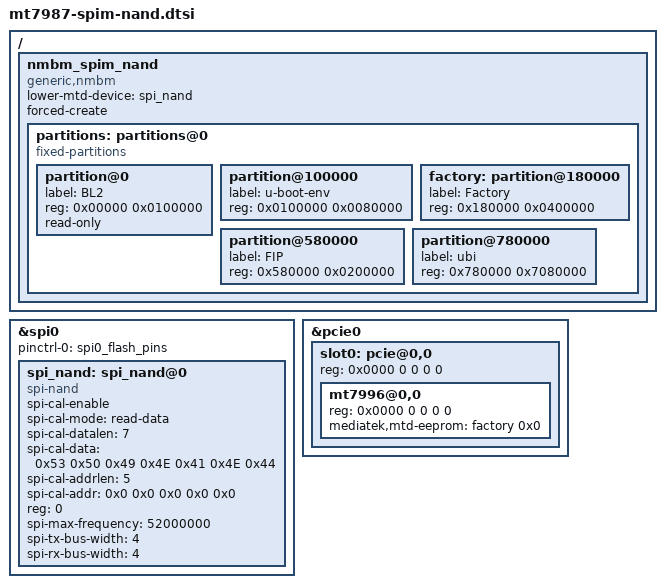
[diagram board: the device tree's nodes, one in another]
/* SPDX-License-Identifier: (GPL-2.0-only OR MIT) */

#include "mt7987-pinctrl.dtsi"

/ {
	nmbm_spim_nand {
		compatible = "generic,nmbm";

		#address-cells = <1>;
		#size-cells = <1>;

		lower-mtd-device = <&spi_nand>;
		forced-create;

		partitions: partitions@0 {
			compatible = "fixed-partitions";
			#address-cells = <1>;
			#size-cells = <1>;
		};
	};
};

&partitions {
	partition@0 {
		label = "BL2";
		reg = <0x00000 0x0100000>;
		read-only;
	};
	partition@100000 {
		label = "u-boot-env";
		reg = <0x0100000 0x0080000>;
	};
	factory: partition@180000 {
		label = "Factory";
		reg = <0x180000 0x0400000>;
	};
	partition@580000 {
		label = "FIP";
		reg = <0x580000 0x0200000>;
	};
	partition@780000 {
		label = "ubi";
		reg = <0x780000 0x7080000>;
	};
};

&spi0 {
	pinctrl-names = "default";
	pinctrl-0 = <&spi0_flash_pins>;
	status = "okay";
	#address-cells = <1>;
	#size-cells = <0>;

	spi_nand: spi_nand@0 {
		#address-cells = <1>;
		#size-cells = <1>;
		compatible = "spi-nand";
		spi-cal-enable;
		spi-cal-mode = "read-data";
		spi-cal-datalen = <7>;
		spi-cal-data = /bits/ 8 <0x53 0x50 0x49 0x4E 0x41 0x4E 0x44>;
		spi-cal-addrlen = <5>;
		spi-cal-addr = /bits/ 32 <0x0 0x0 0x0 0x0 0x0>;
		reg = <0>;
		spi-max-frequency = <52000000>;
		spi-tx-bus-width = <4>;
		spi-rx-bus-width = <4>;
	};
};

&pcie0 {
	/* slot0 is used for MT76 only */
	slot0: pcie@0,0 {
		reg = <0x0000 0 0 0 0>;

		mt7996@0,0 {
			reg = <0x0000 0 0 0 0>;
			device_type = "pci";
			mediatek,mtd-eeprom = <&factory 0x0>;
		};
	};
};
